# LCD_CTRL: IP-XACT component
VLNV local:lcd:LCD_CTRL:1.0
SPI LCD Controller with Integrated DMA Engine - GC9306X primary target

## Bus interfaces (logical=physical port)
APB_slave: slave amba.com:AMBA3:APB:1.0, memory map regMap
  PCLK=clk, PRESETn=rst_n, PSEL=PSEL, PENABLE=PENABLE, PWRITE=PWRITE, PADDR=PADDR, PWDATA=PWDATA, PRDATA=PRDATA, PREADY=PREADY, PSLVERR=PSLVERR

## Ports
in clk
in rst_n
in PSEL
in PENABLE
in PWRITE
in PADDR[31:0]
in PWDATA[31:0]
out PRDATA[31:0]
out PREADY
out PSLVERR

## Address spaces and blocks
regMap.lcd_registers: base 0x0, range 0x100, width 32, register

## Registers
Registers are 32-bit, read-write, reset 0x0 unless marked. A register's access mark holds for its fields unless they carry their own. Offsets are from the block's base; lines under a group give offsets from that group; [hi:lo] are bit positions; {n}, {i} and the like mark numbered series; 'fields as' and 'values as' point back to an identical list; <NAME> marks a mode.

## regMap.lcd_registers
Base 0x00000000
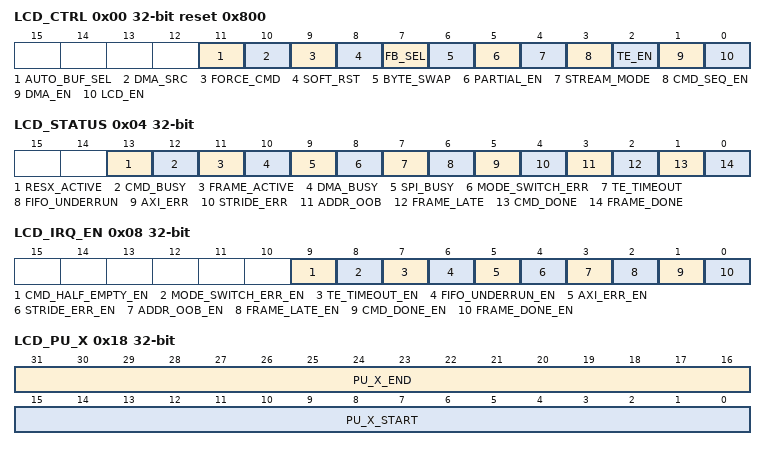
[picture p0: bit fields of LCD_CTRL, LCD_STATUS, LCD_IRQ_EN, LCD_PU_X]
0x00 LCD_CTRL reset 0x800 — Master enable. Clears cleanly with SOFT_RST.
  [11] AUTO_BUF_SEL — AXI slave buffer routing: 1=auto-route to AXI_OWN buffer, 0=explicit AWADDR. Idle-only change.
  [10] DMA_SRC — Pixel source: 0=DMA engine (default), 1=AXI slave port. Idle-only change.
  [9] FORCE_CMD write-clears — Self-clearing. Forces immediate CMD FIFO drain, bypassing frame FSM.
  [8] SOFT_RST write-clears — Self-clearing. Resets all internal state except RESX output.
  [7] FB_SEL — Latched at trigger. Select active frame buffer: 0=FB0, 1=FB1.
  [6] BYTE_SWAP — 0=MSB first (GC9306X native), 1=LSB first. Latched at trigger.
  [5] PARTIAL_EN — Enable partial update region (LCD_PU_X/Y). Latched at trigger.
  [4] STREAM_MODE — CS# stays LOW across frames, CMD skipped after first. Latch-at-trigger.
  [3] CMD_SEQ_EN — Enable auto CASET/PASET/RAMWR sequence before pixel burst.
  [2] TE_EN — Enable TE synchronization. Frame trigger waits for TE edge.
  [1] DMA_EN — Enable DMA engine for autonomous frame fetch from system memory.
  [0] LCD_EN — Master enable. Clears cleanly with SOFT_RST.
0x04 LCD_STATUS — Set when complete frame transmitted to display. Write 1 to clear.
  [13] RESX_ACTIVE ro — Live: RESX pulse or post-reset delay in progress.
  [12] CMD_BUSY ro — Live: Command path is draining CMD FIFO.
  [11] FRAME_ACTIVE ro — Live: Frame transfer in progress (DMA+SPI inclusive).
  [10] DMA_BUSY ro — Live: DMA engine is performing AXI read burst.
  [9] SPI_BUSY ro — Live: SPI engine is actively clocking data.
  [8] MODE_SWITCH_ERR write-1-clears — SPI_CFG written while SPI_BUSY=1. Write 1 to clear.
  [7] TE_TIMEOUT write-1-clears — TE_TIMEOUT period expired with no TE edge. Write 1 to clear.
  [6] FIFO_UNDERRUN write-1-clears — TX FIFO emptied mid-row during SPI drain. Critical. Write 1 to clear.
  [5] AXI_ERR write-1-clears — Set on AXI RRESP != OKAY during DMA burst. ERR_ADDR latched. Write 1 to clear.
  [4] STRIDE_ERR write-1-clears — STRIDE too small or not aligned. DMA aborted. Write 1 to clear.
  [3] ADDR_OOB write-1-clears — Set when DMA address exceeds validated AXI region. Write 1 to clear.
  [2] FRAME_LATE write-1-clears — Set when new TE edge arrives before current frame completes. Write 1 to clear.
  [1] CMD_DONE write-1-clears — Set when CMD FIFO drains completely. Write 1 to clear.
  [0] FRAME_DONE write-1-clears — Set when complete frame transmitted to display. Write 1 to clear.
0x08 LCD_IRQ_EN — Enable FRAME_DONE interrupt.
  [9] CMD_HALF_EMPTY_EN — Enable IRQ when CMD FIFO drops below half-full.
  [8] MODE_SWITCH_ERR_EN — Enable MODE_SWITCH_ERR interrupt.
  [7] TE_TIMEOUT_EN — Enable TE_TIMEOUT interrupt.
  [6] FIFO_UNDERRUN_EN — Enable FIFO_UNDERRUN interrupt.
  [5] AXI_ERR_EN — Enable AXI_ERR interrupt.
  [4] STRIDE_ERR_EN — Enable STRIDE_ERR interrupt.
  [3] ADDR_OOB_EN — Enable ADDR_OOB interrupt.
  [2] FRAME_LATE_EN — Enable FRAME_LATE interrupt.
  [1] CMD_DONE_EN — Enable CMD_DONE interrupt.
  [0] FRAME_DONE_EN — Enable FRAME_DONE interrupt.
0x0C LCD_FB0_ADDR — AXI base address of frame buffer 0. Bits[1:0] must be 0. Latched at DMA trigger.
  [31:0] FB0_ADDR
0x10 LCD_FB1_ADDR — AXI base address of frame buffer 1. Bits[1:0] must be 0. Latched at DMA trigger.
  [31:0] FB1_ADDR
0x14 LCD_STRIDE — Row stride in bytes. QVGA=480, VGA=1280. Multiple of AXI data width. Latched at DMA trigger.
  [15:0] STRIDE
0x18 LCD_PU_X — Start column 0-based inclusive. SC value for CASET. Latched at DMA trigger.
  [31:16] PU_X_END — End column 0-based inclusive. EC value for CASET. Latched at DMA trigger.
  [15:0] PU_X_START — Start column 0-based inclusive. SC value for CASET. Latched at DMA trigger.
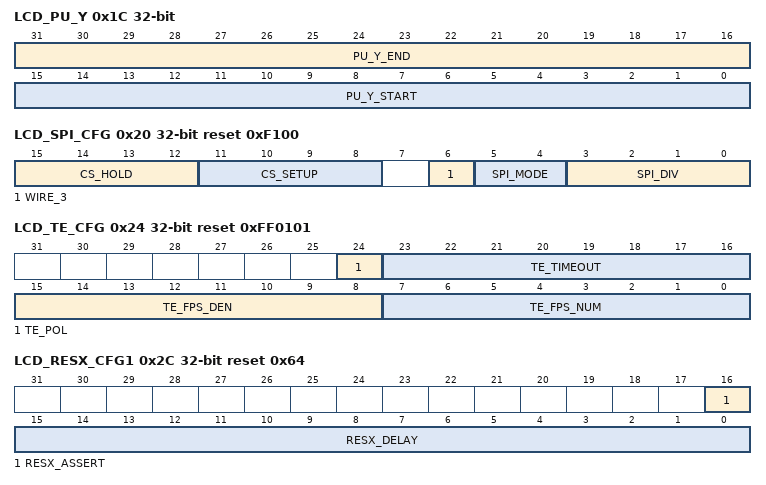
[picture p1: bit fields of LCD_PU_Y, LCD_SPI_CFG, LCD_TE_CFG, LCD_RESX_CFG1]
0x1C LCD_PU_Y — Start row 0-based inclusive. SP value for PASET. Latched at DMA trigger.
  [31:16] PU_Y_END — End row 0-based inclusive. EP value for PASET. Latched at DMA trigger.
  [15:0] PU_Y_START — Start row 0-based inclusive. SP value for PASET. Latched at DMA trigger.
0x20 LCD_SPI_CFG reset 0xF100 — SPI clock divider. SCK = sys_clk / (2*(SPI_DIV+1)). GC9306X target: SPI_DIV=4 @ 100MHz -> 10MHz.
  [15:12] CS_HOLD — CS# hold cycles between last SCK edge and CS# de-assertion. Min 5 @ 100MHz (50ns >= GC9306X 40ns).
  [11:8] CS_SETUP — CS# setup cycles between CS# assertion and first SCK edge. Min 3 @ 100MHz (30ns >= GC9306X 20ns).
  [6] WIRE_3 — 0=4-wire SPI (separate spi_dc pin), 1=3-wire SPI (D/C embedded as 9th bit).
  [5:4] SPI_MODE — SPI clock polarity/phase: 0=Mode0(CPOL=0/CPHA=0), 1=Mode1, 2=Mode2, 3=Mode3.
  [3:0] SPI_DIV — SPI clock divider. SCK = sys_clk / (2*(SPI_DIV+1)). GC9306X target: SPI_DIV=4 @ 100MHz -> 10MHz.
0x24 LCD_TE_CFG reset 0xFF0101 — Bresenham numerator: target FPS (e.g. 24). Divider passes TE_FPS_NUM of every TE_FPS_DEN pulses.
  [24] TE_POL — TE input polarity: 0=trigger on rising edge (GC9306X default, V-blank HIGH), 1=falling edge.
  [23:16] TE_TIMEOUT — Timeout in TE periods (10ms units @ 100MHz). 0=disabled. If no TE edge, assert TE_TIMEOUT IRQ.
  [15:8] TE_FPS_DEN — Bresenham denominator: display TE rate in Hz (e.g. 60). 0 treated as 1 (divide-by-zero protection).
  [7:0] TE_FPS_NUM — Bresenham numerator: target FPS (e.g. 24). Divider passes TE_FPS_NUM of every TE_FPS_DEN pulses.
0x28 LCD_RESX_CFG0 reset 0x64 — RESX pulse width in sys_clk cycles. GC9306X requires >= 10us low (1000 cycles @ 100MHz).
  [15:0] RESX_WIDTH
0x2C LCD_RESX_CFG1 reset 0x64 — Delay in sys_clk cycles after RESX de-assertion before RESX_DONE is set. GC9306X requires >= 5ms.
  [16] RESX_ASSERT write-clears — Self-clearing. Write 1 to trigger RESX pulse sequence. Cleared when sequence starts.
  [15:0] RESX_DELAY — Delay in sys_clk cycles after RESX de-assertion before RESX_DONE is set. GC9306X requires >= 5ms.
0x30 LCD_CMD_FIFO wo — Write-only FIFO push port. Bits[7:0]=CMD_BYTE, Bits[23:16]=PAYLOAD_LEN. Hardware decodes internally.
  [31:0] CMD_ENTRY
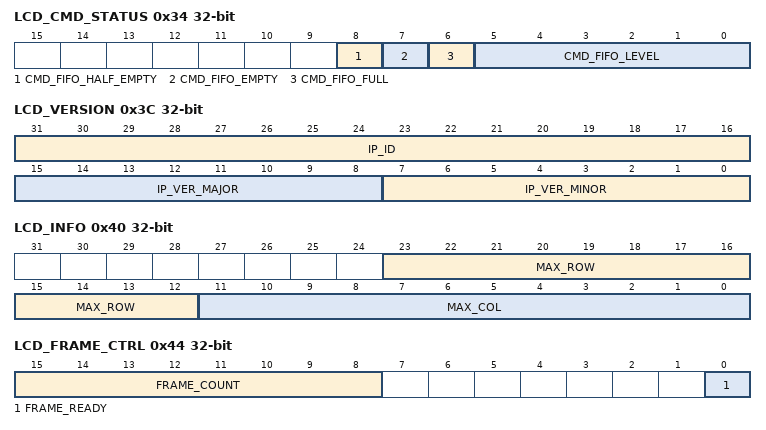
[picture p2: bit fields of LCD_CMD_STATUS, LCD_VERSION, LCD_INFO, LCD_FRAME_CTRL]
0x34 LCD_CMD_STATUS ro reset not defined — Current number of entries in CMD FIFO (0-63).
  [8] CMD_FIFO_HALF_EMPTY — Asserted when CMD FIFO level < 32. Use with CMD_HALF_EMPTY_EN for IRQ-driven write.
  [7] CMD_FIFO_EMPTY — Asserted when CMD FIFO is empty.
  [6] CMD_FIFO_FULL — Asserted when CMD FIFO contains 64 entries.
  [5:0] CMD_FIFO_LEVEL — Current number of entries in CMD FIFO (0-63).
0x38 LCD_ERR_ADDR ro reset not defined — AXI read address that triggered last DMA fault (ADDR_OOB or AXI_ERR). Debug use.
  [31:0] ERR_ADDR
0x3C LCD_VERSION ro reset not defined — Minor version number. Synthesis parameter IP_VER_MINOR. Default 0x00 for v1.0.
  [31:16] IP_ID — IP identifier constant. Synthesis parameter IP_ID. Default 0xAC1D for silicon ID.
  [15:8] IP_VER_MAJOR — Major version number. Synthesis parameter IP_VER_MAJOR. Default 0x01 for v1.x.
  [7:0] IP_VER_MINOR — Minor version number. Synthesis parameter IP_VER_MINOR. Default 0x00 for v1.0.
0x40 LCD_INFO ro reset not defined — Max column count from synthesis parameter MAX_COL. Default 240 for QVGA, 640 for VGA.
  [23:12] MAX_ROW — Max row count from synthesis parameter MAX_ROW. Default 320 for QVGA, 480 for VGA.
  [11:0] MAX_COL — Max column count from synthesis parameter MAX_COL. Default 240 for QVGA, 640 for VGA.
0x44 LCD_FRAME_CTRL — Write 1 to trigger a frame. Self-clearing. TE mode: arms trigger, DMA starts on next qualifying TE edge.
  [15:8] FRAME_COUNT ro — Rolling 8-bit frame counter. Incremented on each FRAME_DONE. Wraps 255->0. Frame-rate measurement.
  [0] FRAME_READY write-clears — Write 1 to trigger a frame. Self-clearing. TE mode: arms trigger, DMA starts on next qualifying TE edge.
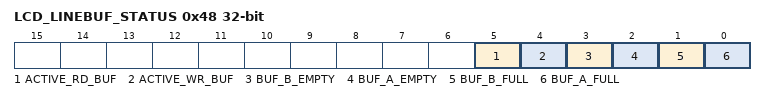
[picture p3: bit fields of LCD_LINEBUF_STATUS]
0x48 LCD_LINEBUF_STATUS ro reset not defined — Line buffer A is full (DMA fill complete for this row).
  [5] ACTIVE_RD_BUF — Current SPI read source: 0=Buffer A, 1=Buffer B.
  [4] ACTIVE_WR_BUF — Current DMA write target: 0=Buffer A, 1=Buffer B.
  [3] BUF_B_EMPTY — Line buffer B is empty.
  [2] BUF_A_EMPTY — Line buffer A is empty (SPI drain complete).
  [1] BUF_B_FULL — Line buffer B is full.
  [0] BUF_A_FULL — Line buffer A is full (DMA fill complete for this row).
0x4C LCD_SLAVE_BUFA_ADDR ro reset not defined — AXI slave Buffer A base address in SoC memory map. Set at integration time via parameter.
  [31:0] BUFA_ADDR
0x50 LCD_SLAVE_BUFB_ADDR ro reset not defined — AXI slave Buffer B base address in SoC memory map. = BUFA_ADDR + LINE_BUF_SIZE.
  [31:0] BUFB_ADDR
0x54 LCD_SLAVE_INFO ro reset not defined — AXI slave total aperture size in bytes. = 2 * LINE_BUF_SIZE. QVGA: 1024 (0x400), VGA: 4096 (0x1000).
  [31:0] APERTURE_SIZE
